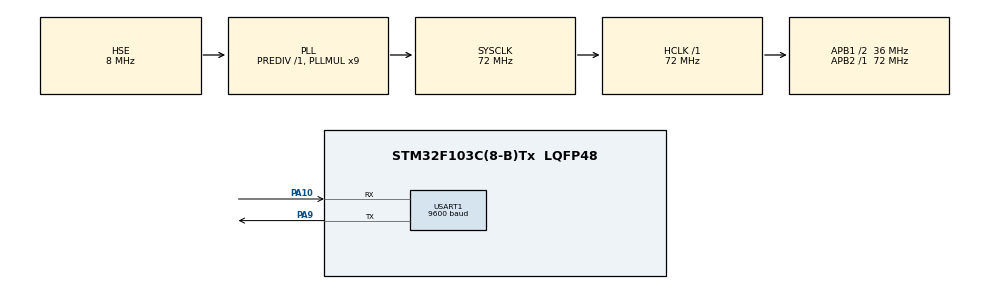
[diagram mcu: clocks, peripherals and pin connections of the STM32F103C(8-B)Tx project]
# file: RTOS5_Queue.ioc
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FREERTOS.Queues01=myQueue01,5,uint16_t,0,Dynamic,NULL,NULL
FREERTOS.Tasks01=Sender1Task,0,128,StartTask,Default,NULL,Dynamic,NULL,NULL;myTask02,-3,128,StartTask02,Default,NULL,Dynamic,NULL,NULL;myTask03,-3,128,StartTask03,Default,NULL,Dynamic,NULL,NULL
Mcu.Family=STM32F1
Mcu.Name=STM32F103C(8-B)Tx
Mcu.Package=LQFP48
NVIC.PriorityGroup=NVIC_PRIORITYGROUP_4
NVIC.TIM1_UP_IRQn=true\:0\:0\:false\:false\:true\:false\:false\:true
NVIC.TimeBase=TIM1_UP_IRQn
NVIC.TimeBaseIP=TIM1
NVIC.USART1_IRQn=true\:0\:0\:false\:false\:true\:false\:true\:true
PA10.Mode=Asynchronous
PA10.Signal=USART1_RX
PA13.Mode=Serial_Wire
PA13.Signal=SYS_JTMS-SWDIO
PA14.Mode=Serial_Wire
PA14.Signal=SYS_JTCK-SWCLK
PA9.Mode=Asynchronous
PA9.Signal=USART1_TX
PD0-OSC_IN.Mode=HSE-External-Oscillator
PD0-OSC_IN.Signal=RCC_OSC_IN
PD1-OSC_OUT.Mode=HSE-External-Oscillator
PD1-OSC_OUT.Signal=RCC_OSC_OUT
ProjectManager.HeapSize=0x200
ProjectManager.StackSize=0x400
ProjectManager.TargetToolchain=MDK-ARM V5.27
RCC.AHBFreq_Value=72000000
RCC.APB1CLKDivider=RCC_HCLK_DIV2
RCC.APB1Freq_Value=36000000
RCC.APB1TimFreq_Value=72000000
RCC.APB2Freq_Value=72000000
RCC.APB2TimFreq_Value=72000000
RCC.HCLKFreq_Value=72000000
RCC.PLLMUL=RCC_PLL_MUL9
RCC.PLLSourceVirtual=RCC_PLLSOURCE_HSE
RCC.SYSCLKFreq_VALUE=72000000
RCC.SYSCLKSource=RCC_SYSCLKSOURCE_PLLCLK
RCC.USBFreq_Value=72000000
USART1.BaudRate=9600
USART1.VirtualMode=VM_ASYNC
VP_FREERTOS_VS_CMSIS_V1.Mode=CMSIS_V1
VP_SYS_VS_tim1.Mode=TIM1
board=custom

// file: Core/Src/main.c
/* USER CODE BEGIN Header */
/**
  ******************************************************************************
  * @file           : main.c
  * @brief          : Main program body
  ******************************************************************************
  * @attention
  *
  * <h2><center>&copy; Copyright (c) 2020 STMicroelectronics.
  * All rights reserved.</center></h2>
  *
  * This software component is licensed by ST under Ultimate Liberty license
  * SLA0044, the "License"; You may not use this file except in compliance with
  * the License. You may obtain a copy of the License at:
  *                             www.st.com/SLA0044
  *
  ******************************************************************************
  */
/* USER CODE END Header */
#include "main.h"

/* USER CODE BEGIN Includes */
#include "FreeRTOS.h"
#include "task.h"
#include "timers.h"
#include "queue.h"
#include "semphr.h"
#include "event_groups.h"
#include "string.h"
#include "stdio.h"

/* USER CODE END Includes */

UART_HandleTypeDef huart1;
QueueHandle_t xMyQueue;
/* USER CODE BEGIN PV */
char *pcStrings;
uint8_t ucReceiveData;
/* USER CODE END PV */

void SystemClock_Config(void);
static void MX_GPIO_Init(void);
static void MX_USART1_UART_Init(void);
void vSenderTask(void *pvParameters);
void vReceiverTask(void *pvParameters);

int main(void)
{

  /* MCU Configuration--------------------------------------------------------*/

  /* Reset of all peripherals, Initializes the Flash interface and the Systick. */
  HAL_Init();

  /* Configure the system clock */
  SystemClock_Config();

  /* Initialize all configured peripherals */
  MX_GPIO_Init();
  MX_USART1_UART_Init();
  /* USER CODE BEGIN 2 */
  HAL_UART_Receive_IT(&huart1, &ucReceiveData, 1);
  /* USER CODE END 2 */

  /* Create the queue(s) */
  /* creation of xQueue */
  xMyQueue = xQueueCreate(5, sizeof(uint16_t));
  if (xMyQueue == 0)
  {
    pcStrings = "Unable to create Unsigned Short\r\n\r\n";
    HAL_UART_Transmit(&huart1, (uint8_t *)pcStrings, strlen(pcStrings), 200);
  }
  else
  {
    pcStrings = "Unsigned Short Queue created successfuly\r\n\r\n";
    HAL_UART_Transmit(&huart1, (uint8_t *)pcStrings, strlen(pcStrings), 200);
  }

  /* Create the thread(s) */
  /* creation of Sender1Task */
  xTaskCreate(vSenderTask, "Sender 1", 128, (void *)111, 1, NULL);

  /* creation of Sender2Task */
  //xTaskCreate(vSenderTask, "Sender 2", 128, (void *)222, 2, NULL);

  /* creation of ReceiverTask */
  xTaskCreate(vReceiverTask, "Receiver", 128, NULL, 3, NULL);

  /* Start scheduler */
  vTaskStartScheduler();

  /* We should never get here as control is now taken by the scheduler */
  /* Infinite loop */
  while (1)
  {

  }
}

void SystemClock_Config(void)
{
  RCC_OscInitTypeDef RCC_OscInitStruct = {0};
  RCC_ClkInitTypeDef RCC_ClkInitStruct = {0};

  /** Initializes the RCC Oscillators according to the specified parameters
  * in the RCC_OscInitTypeDef structure.
  */
  RCC_OscInitStruct.OscillatorType = RCC_OSCILLATORTYPE_HSE;
  RCC_OscInitStruct.HSEState = RCC_HSE_ON;
  RCC_OscInitStruct.HSEPredivValue = RCC_HSE_PREDIV_DIV1;
  RCC_OscInitStruct.HSIState = RCC_HSI_ON;
  RCC_OscInitStruct.PLL.PLLState = RCC_PLL_ON;
  RCC_OscInitStruct.PLL.PLLSource = RCC_PLLSOURCE_HSE;
  RCC_OscInitStruct.PLL.PLLMUL = RCC_PLL_MUL9;
  if (HAL_RCC_OscConfig(&RCC_OscInitStruct) != HAL_OK)
  {
    Error_Handler();
  }
  /** Initializes the CPU, AHB and APB buses clocks
  */
  RCC_ClkInitStruct.ClockType = RCC_CLOCKTYPE_HCLK|RCC_CLOCKTYPE_SYSCLK
                              |RCC_CLOCKTYPE_PCLK1|RCC_CLOCKTYPE_PCLK2;
  RCC_ClkInitStruct.SYSCLKSource = RCC_SYSCLKSOURCE_PLLCLK;
  RCC_ClkInitStruct.AHBCLKDivider = RCC_SYSCLK_DIV1;
  RCC_ClkInitStruct.APB1CLKDivider = RCC_HCLK_DIV2;
  RCC_ClkInitStruct.APB2CLKDivider = RCC_HCLK_DIV1;

  if (HAL_RCC_ClockConfig(&RCC_ClkInitStruct, FLASH_LATENCY_2) != HAL_OK)
  {
    Error_Handler();
  }
}

static void MX_USART1_UART_Init(void)
{

  huart1.Instance = USART1;
  huart1.Init.BaudRate = 9600;
  huart1.Init.WordLength = UART_WORDLENGTH_8B;
  huart1.Init.StopBits = UART_STOPBITS_1;
  huart1.Init.Parity = UART_PARITY_NONE;
  huart1.Init.Mode = UART_MODE_TX_RX;
  huart1.Init.HwFlowCtl = UART_HWCONTROL_NONE;
  huart1.Init.OverSampling = UART_OVERSAMPLING_16;
  if (HAL_UART_Init(&huart1) != HAL_OK)
  {
    Error_Handler();
  }

}

static void MX_GPIO_Init(void)
{

  /* GPIO Ports Clock Enable */
  __HAL_RCC_GPIOD_CLK_ENABLE();
  __HAL_RCC_GPIOA_CLK_ENABLE();

}

/* USER CODE BEGIN 4 */
void HAL_UART_RxCpltCallback(UART_HandleTypeDef *huart)
{
  HAL_UART_Receive_IT(&huart1, &ucReceiveData, 1);
  uint16_t usValueToSend = 12345;
  BaseType_t xHigherPriorityTaskWoken = pdFALSE;
  char *pcStringSendFromISR = "Sent from ISR\r\n\r\n";
  if (ucReceiveData == 'r')
  {
    if (xQueueSendToFrontFromISR(xMyQueue, &usValueToSend, &xHigherPriorityTaskWoken) == pdPASS)
    {
      HAL_UART_Transmit(&huart1, (uint8_t *)pcStringSendFromISR, strlen(pcStringSendFromISR), 100);
    }
    portYIELD_FROM_ISR(xHigherPriorityTaskWoken);
  }

}
/* USER CODE END 4 */

void vSenderTask(void *pvParameters)
{
  /* USER CODE BEGIN 5 */
  const TickType_t xTicksToWait = pdMS_TO_TICKS(2000);
  uint32_t ulValueToSend;
  char *pcStringFromSender;
  ulValueToSend = (uint32_t)pvParameters;
  /* Infinite loop */
  for(;;)
  {
    if (xQueueSendToFront(xMyQueue, &ulValueToSend, portMAX_DELAY)==pdPASS)
    {
      if (ulValueToSend == 111)
      {
        pcStringFromSender = "Successfully sent the number to the queue\n Leaving Sender 1\r\n\r\n";
      }
      else
      {
        pcStringFromSender = "Successfully sent the number to the queue\n Leaving Sender 2\r\n\r\n";
      }
    }
    HAL_UART_Transmit(&huart1, (uint8_t *) pcStringFromSender, strlen(pcStringFromSender), 500);
    vTaskDelay(xTicksToWait);
  }
  /* USER CODE END 5 */
}

void vReceiverTask(void *pvParameters)
{
  /* USER CODE BEGIN ReceiverTask */
  uint16_t usReceiveValue = 0;
  const TickType_t xTicksToWait = pdMS_TO_TICKS(3000);
  char *pcStringFromReceiver;
  /* Infinite loop */
  for(;;)
  {
    if (xQueueReceive(xMyQueue, &usReceiveValue, portMAX_DELAY)!=pdPASS)
    {
      pcStringFromReceiver = "Error in Receiving from Queue\r\n\r\n";
      HAL_UART_Transmit(&huart1, (uint8_t *)pcStringFromReceiver, strlen(pcStringFromReceiver), 300);
    }
    else
    {
      sprintf(pcStringFromReceiver,"Successfully Received the number %d to the Queue\n Leaving Receiver Task\r\n\r\n", usReceiveValue);
      HAL_UART_Transmit(&huart1, (uint8_t *)pcStringFromReceiver, strlen(pcStringFromReceiver), 500);
    }
    vTaskDelay(xTicksToWait);
  }
  /* USER CODE END ReceiverTask */
}

void HAL_TIM_PeriodElapsedCallback(TIM_HandleTypeDef *htim)
{
  if (htim->Instance == TIM1) {
    HAL_IncTick();
  }
}

void Error_Handler(void)
{
}

/************************ (C) COPYRIGHT STMicroelectronics *****END OF FILE****/
